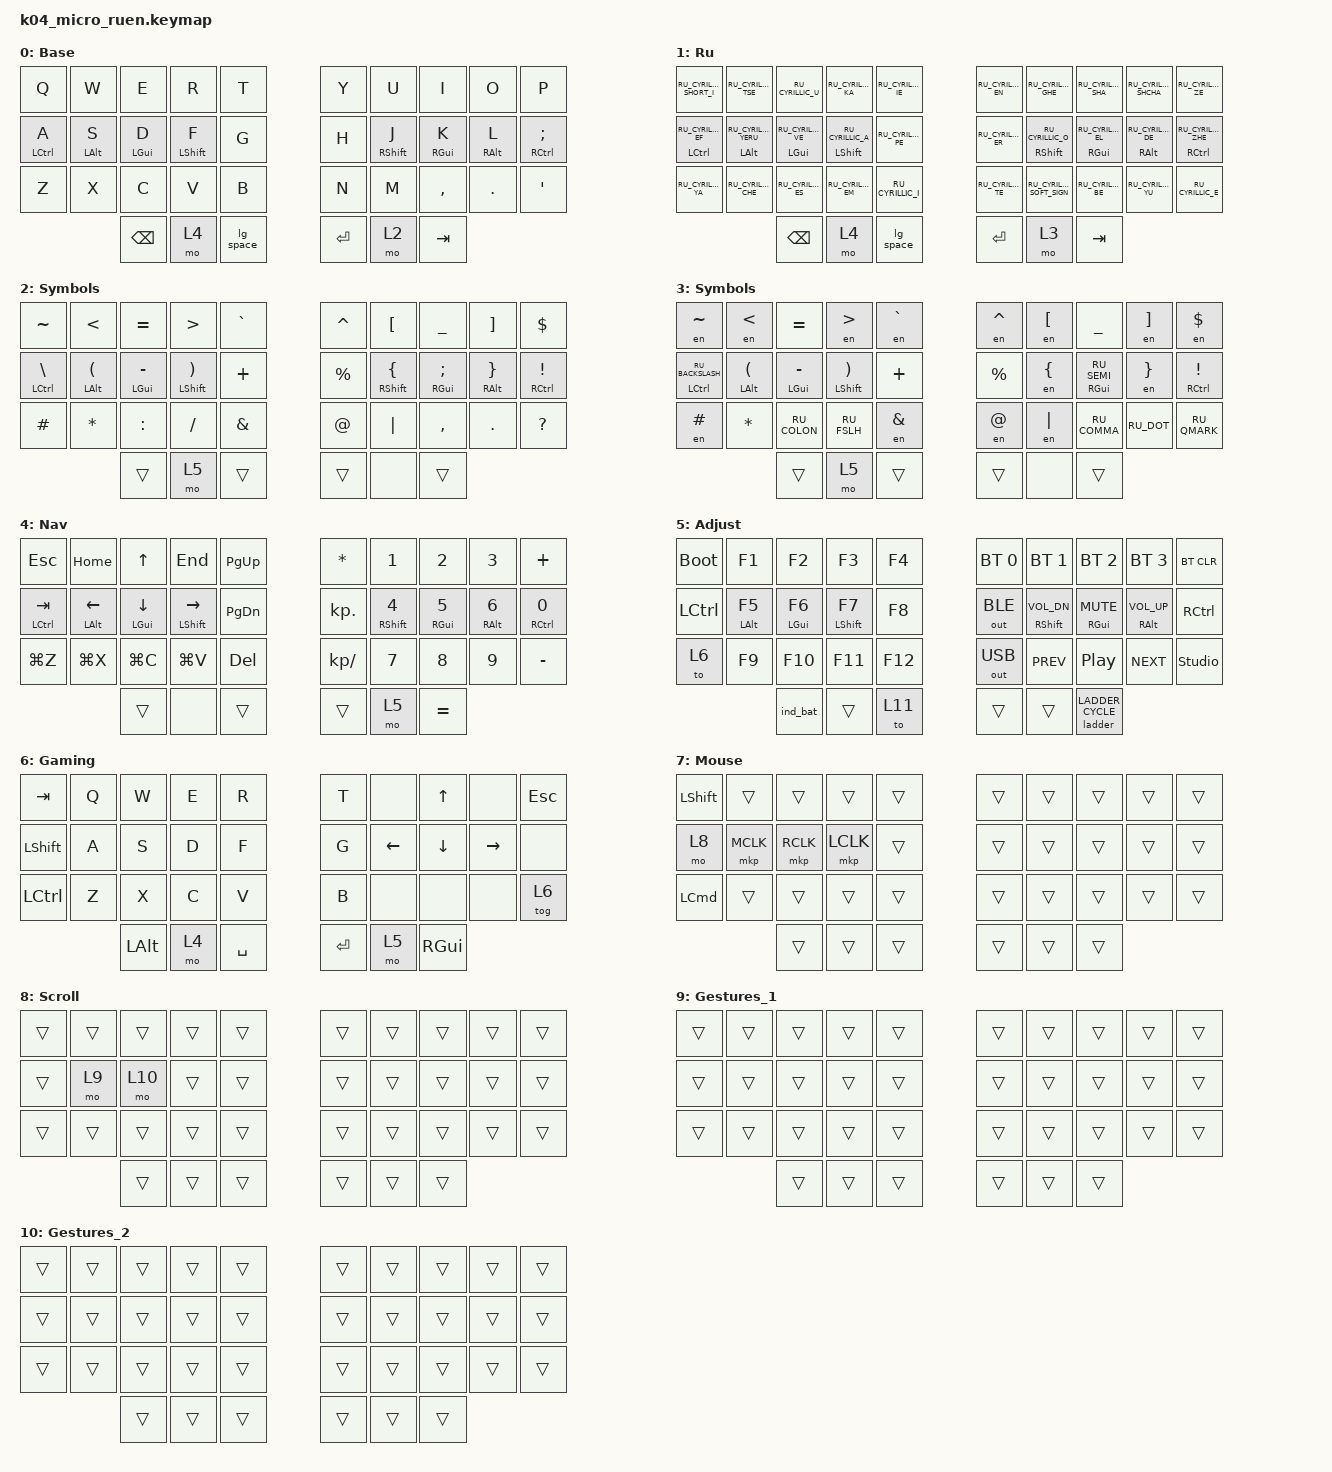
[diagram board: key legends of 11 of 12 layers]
/*
 * K:04 Micro — RU/EN вариант (аналог op36_ruen.keymap)
 * Слой Mouse включается сам при движении трекбола (zip_auto_mouse).
 */

#include "keys_ru.h"
#include <dt-bindings/zmk/input_transform.h>
#include <input/processors.dtsi>
#include <zephyr/dt-bindings/input/input-event-codes.h>
#include <behaviors/input_gestures_accel.dtsi>
#include <dt-bindings/zmk/mouse-gesture.h>
#include <behaviors.dtsi>
#include <behaviors/split_conn_ladder.dtsi>
#include <dt-bindings/zmk/split_conn_ladder.h>
#include <behaviors/ble_host_link.dtsi>
#include <dt-bindings/zmk/ble_host_link.h>
#include <dt-bindings/zmk/bt.h>
#include <dt-bindings/zmk/keys.h>
#include <dt-bindings/zmk/outputs.h>
#include <dt-bindings/zmk/pointing.h>

/ {
    input_processors {
        xy_fine: xy_fine {
            compatible = "zmk,input-processor-scaler";
            #input-processor-cells = <2>;
            type = <INPUT_EV_REL>;
            codes = <INPUT_REL_X INPUT_REL_Y>;
            track-remainders;
        };
    };

    accel_scroll: accel_scroll {
        compatible = "zmk,input-processor-acceleration";
        status = "okay";
        #input-processor-cells = <0>;
        input-type = <INPUT_EV_REL>;
        track-remainders;
        min-factor = <1000>;
        max-factor = <8000>;
        speed-threshold = <1000>;
        speed-max = <12000>;
        acceleration-exponent = <3>;
    };

    gest_layer_1: gest_layer_1 {
        compatible = "zmk,input-processor-mouse-gesture";
        #input-processor-cells = <0>;
        always-active;
        enable-eager-mode;
        suppress-movement;
        stroke-size = <120>;
        movement-threshold = <2>;
        gesture-cooldown-ms = <250>;

        gu {
            pattern = <GESTURE_UP>;
            bindings = <&gl_1_u>;
        };

        gd {
            pattern = <GESTURE_DOWN>;
            bindings = <&gl_1_d>;
        };

        gl {
            pattern = <GESTURE_LEFT>;
            bindings = <&gl_1_l>;
        };

        gr {
            pattern = <GESTURE_RIGHT>;
            bindings = <&gl_1_r>;
        };
    };

    gest_layer_2: gest_layer_2 {
        compatible = "zmk,input-processor-mouse-gesture";
        #input-processor-cells = <0>;
        always-active;
        enable-eager-mode;
        suppress-movement;
        stroke-size = <120>;
        movement-threshold = <2>;
        gesture-cooldown-ms = <250>;

        gu {
            pattern = <GESTURE_UP>;
            bindings = <&gl_2_u>;
        };

        gd {
            pattern = <GESTURE_DOWN>;
            bindings = <&gl_2_d>;
        };

        gl {
            pattern = <GESTURE_LEFT>;
            bindings = <&gl_2_l>;
        };

        gr {
            pattern = <GESTURE_RIGHT>;
            bindings = <&gl_2_r>;
        };
    };
};

&pointer_accel {
    input-type = <INPUT_EV_REL>;
    track-remainders;
    min-factor = <1000>;
    max-factor = <6000>;
    speed-threshold = <100>;
    speed-max = <16000>;
    acceleration-exponent = <2>;
};

&mt {
    quick-tap-ms = <200>;
    flavor = "tap-preferred";
    require-prior-idle-ms = <125>;
};

/ {
    behaviors {
        zip_auto_mouse: zip_auto_mouse {
            compatible = "zmk,input-processor-temp-layer-keep";
            #input-processor-cells = <2>;
            require-prior-idle-ms = <300>;
            excluded-positions = <0 10 11 12 13 20>;
            keep-active-while-layers = <8 9 10>;
        };

        hml: home_row_mod_left {
            compatible = "zmk,behavior-hold-tap";
            #binding-cells = <2>;
            flavor = "balanced";
            require-prior-idle-ms = <150>;
            tapping-term-ms = <280>;
            quick-tap-ms = <175>;
            bindings = <&kp>, <&kp>;

            hold-trigger-key-positions = <5 6 7 8 9 15 16 17 18 19 25 26 27 28 29 33 34 35 32>;
            hold-trigger-on-release;
        };

        hmr: home_row_mod_right {
            compatible = "zmk,behavior-hold-tap";
            #binding-cells = <2>;
            flavor = "balanced";
            require-prior-idle-ms = <150>;
            tapping-term-ms = <280>;
            quick-tap-ms = <175>;
            bindings = <&kp>, <&kp>;

            hold-trigger-key-positions = <0 1 2 3 4 10 11 12 13 14 20 21 22 23 24 30 31 32>;
            hold-trigger-on-release;
        };

        lg_space: lg_space {
            compatible = "zmk,behavior-mod-morph";
            label = "toggle 'ru' layer with LGUI";
            bindings = <&kp SPACE>, <&lg_tog>;

            #binding-cells = <0>;
            mods = <(MOD_LGUI|MOD_RGUI)>;
        };
    };

    combos {
        compatible = "zmk,combos";

        kha {
            bindings = <&kp RU_CYRILLIC_HA>;
            key-positions = <6 7>;
            layers = <1>;
        };

        hrdsgn {
            bindings = <&kp RU_CYRILLIC_HARD_SIGN>;
            key-positions = <7 8>;
            layers = <1>;
        };

        ru_io {
            bindings = <&kp RU_CYRILLIC_IO>;
            key-positions = <3 4>;
            layers = <1>;
        };

        cmbenru {
            bindings = <&tog 1>;
            key-positions = <2 3>;
            layers = <0 1>;
        };
    };

    macros {
        gl_1_u: gl_1_u {
            compatible = "zmk,behavior-macro";
            #binding-cells = <0>;
            display-name = "Gesture Up (1)";
            bindings = <&kp LC(UP)>;
            wait-ms = <0>;
            tap-ms = <30>;
        };

        gl_1_d: gl_1_d {
            compatible = "zmk,behavior-macro";
            #binding-cells = <0>;
            display-name = "Gesture Down (1)";
            bindings = <&none>;
            wait-ms = <0>;
            tap-ms = <30>;
        };

        gl_1_l: gl_1_l {
            compatible = "zmk,behavior-macro";
            #binding-cells = <0>;
            display-name = "Gesture Left (1)";
            bindings = <&kp LG(C)>;
            wait-ms = <0>;
            tap-ms = <30>;
        };

        gl_1_r: gl_1_r {
            compatible = "zmk,behavior-macro";
            #binding-cells = <0>;
            display-name = "Gesture Right (1)";
            bindings = <&kp LG(V)>;
            wait-ms = <0>;
            tap-ms = <30>;
        };

        gl_2_u: gl_2_u {
            compatible = "zmk,behavior-macro";
            #binding-cells = <0>;
            display-name = "Gesture Up (2)";
            bindings = <&kp LS(LC(TAB))>;
            wait-ms = <0>;
            tap-ms = <30>;
        };

        gl_2_d: gl_2_d {
            compatible = "zmk,behavior-macro";
            #binding-cells = <0>;
            display-name = "Gesture Down (2)";
            bindings = <&kp LC(TAB)>;
            wait-ms = <0>;
            tap-ms = <30>;
        };

        gl_2_l: gl_2_l {
            compatible = "zmk,behavior-macro";
            #binding-cells = <0>;
            display-name = "Gesture Left (2)";
            bindings = <&kp LG(W)>;
            wait-ms = <0>;
            tap-ms = <30>;
        };

        gl_2_r: gl_2_r {
            compatible = "zmk,behavior-macro";
            #binding-cells = <0>;
            display-name = "Gesture Right (2)";
            bindings = <&kp LG(T)>;
            wait-ms = <0>;
            tap-ms = <30>;
        };

        to_ru: to_ru {
            compatible = "zmk,behavior-macro";
            #binding-cells = <0>;
            bindings = <&kp LG(SPACE)>;
            label = "TO_RU";
            wait-ms = <0>;
            tap-ms = <30>;
        };

        to_en: to_en {
            compatible = "zmk,behavior-macro";
            #binding-cells = <0>;
            bindings = <&kp LG(SPACE)>;
            label = "TO_EN";
            wait-ms = <0>;
            tap-ms = <30>;
        };

        layer_en: layer_en {
            compatible = "zmk,behavior-macro";
            #binding-cells = <0>;
            bindings = <&to 0 &to_en>;
            label = "LAYER_EN";
            wait-ms = <0>;
            tap-ms = <30>;
        };

        layer_ru: layer_ru {
            compatible = "zmk,behavior-macro";
            #binding-cells = <0>;
            bindings = <&to 1 &to_ru>;
            label = "LAYER_RU";
            tap-ms = <30>;
            wait-ms = <0>;
        };

        en: en {
            compatible = "zmk,behavior-macro-one-param";
            #binding-cells = <1>;
            bindings =
                <&to_en>,
                <&macro_press>,
                <&macro_param_1to1 &kp MACRO_PLACEHOLDER>,
                <&macro_pause_for_release>,
                <&macro_release>,
                <&macro_param_1to1 &kp MACRO_PLACEHOLDER>,
                <&macro_tap>,
                <&to_ru>;

            label = "EN";
            wait-ms = <0>;
            tap-ms = <30>;
        };

        lg_tog: lg_tog {
            compatible = "zmk,behavior-macro";
            #binding-cells = <0>;
            bindings = <&kp LG(SPACE) &tog 1>;
            label = "LG_TOG";
        };
    };

    keymap {
        compatible = "zmk,keymap";

        en {
            bindings = <
&kp Q         &kp W        &kp E        &kp R          &kp T                          &kp Y  &kp U         &kp I        &kp O        &kp P
&hml LCTRL A  &hml LALT S  &hml LGUI D  &hml LSHFT F   &kp G                          &kp H  &hmr RSHFT J  &hmr RGUI K  &hmr RALT L  &hmr RCTRL SEMICOLON
&kp Z         &kp X        &kp C        &kp V          &kp B                          &kp N  &kp M         &kp COMMA    &kp DOT      &kp SQT
                                        &kp BACKSPACE  &mo 4  &lg_space    &kp ENTER  &mo 2  &kp TAB
            >;

            display-name = "Base";
        };

        ru {
            bindings = <
&kp RU_CYRILLIC_SHORT_I    &kp RU_CYRILLIC_TSE         &kp RU_CYRILLIC_U         &kp RU_CYRILLIC_KA        &kp RU_CYRILLIC_IE                          &kp RU_CYRILLIC_EN  &kp RU_CYRILLIC_GHE        &kp RU_CYRILLIC_SHA       &kp RU_CYRILLIC_SHCHA     &kp RU_CYRILLIC_ZE
&hml LCTRL RU_CYRILLIC_EF  &hml LALT RU_CYRILLIC_YERU  &hml LGUI RU_CYRILLIC_VE  &hml LSHFT RU_CYRILLIC_A  &kp RU_CYRILLIC_PE                          &kp RU_CYRILLIC_ER  &hmr RSHFT RU_CYRILLIC_O   &hmr RGUI RU_CYRILLIC_EL  &hmr RALT RU_CYRILLIC_DE  &hmr RCTRL RU_CYRILLIC_ZHE
&kp RU_CYRILLIC_YA         &kp RU_CYRILLIC_CHE         &kp RU_CYRILLIC_ES        &kp RU_CYRILLIC_EM        &kp RU_CYRILLIC_I                           &kp RU_CYRILLIC_TE  &kp RU_CYRILLIC_SOFT_SIGN  &kp RU_CYRILLIC_BE        &kp RU_CYRILLIC_YU        &kp RU_CYRILLIC_E
                                                                                 &kp BACKSPACE             &mo 4               &lg_space    &kp ENTER  &mo 3               &kp TAB
            >;

            display-name = "Ru";
        };

        sym_en {
            bindings = <
&kp TILDE        &kp LT          &kp EQUAL        &kp GT           &kp GRAVE                    &kp CARET  &kp LBKT         &kp UNDER       &kp RBKT        &kp DLLR
&hml LCTRL BSLH  &hml LALT LPAR  &hml LGUI MINUS  &hml LSHFT RPAR  &kp PLUS                     &kp PRCNT  &hmr RSHFT LBRC  &hmr RGUI SEMI  &hmr RALT RBRC  &hmr RCTRL EXCL
&kp HASH         &kp STAR        &kp COLON        &kp FSLH         &kp AMPS                     &kp AT     &kp PIPE         &kp COMMA       &kp DOT         &kp QMARK
                                                  &trans           &mo 5      &trans    &trans  &none      &trans
            >;

            display-name = "Symbols";
        };

        sym_ru {
            bindings = <
&en TILDE                &en LT          &kp EQUAL        &en GT           &en GRAVE                    &en CARET  &en LBKT  &kp UNDER          &en RBKT    &en DLLR
&hml LCTRL RU_BACKSLASH  &hml LALT LPAR  &hml LGUI MINUS  &hml LSHFT RPAR  &kp PLUS                     &kp PRCNT  &en LBRC  &hmr RGUI RU_SEMI  &en RBRC    &hmr RCTRL EXCL
&en HASH                 &kp STAR        &kp RU_COLON     &kp RU_FSLH      &en AMPS                     &en AT     &en PIPE  &kp RU_COMMA       &kp RU_DOT  &kp RU_QMARK
                                                          &trans           &mo 5      &trans    &trans  &none      &trans
            >;

            display-name = "Symbols";
        };

        nav {
            bindings = <
&kp ESC         &kp HOME            &kp UP          &kp END           &kp PAGE_UP                      &kp STAR       &kp N1         &kp N2        &kp N3        &kp PLUS
&hml LCTRL TAB  &hml LEFT_ALT LEFT  &hml LGUI DOWN  &hml LSHFT RIGHT  &kp PAGE_DOWN                    &kp KP_DOT     &hmr RSHFT N4  &hmr RGUI N5  &hmr RALT N6  &hmr RCTRL N0
&kp LG(Z)       &kp LG(X)           &kp LG(C)       &kp LG(V)         &kp DELETE                       &kp KP_DIVIDE  &kp N7         &kp N8        &kp N9        &kp MINUS
                                                    &trans            &none          &trans    &trans  &mo 5          &kp EQUAL
            >;

            display-name = "Nav";
        };

        adj {
            bindings = <
&bootloader  &kp F1        &kp F2        &kp F3         &kp F4                     &bt BT_SEL 0  &bt BT_SEL 1         &bt BT_SEL 2      &bt BT_SEL 3        &bt BT_CLR
&kp LCTRL    &hml LALT F5  &hml LGUI F6  &hml LSHFT F7  &kp F8                     &out OUT_BLE  &hmr RSHFT C_VOL_DN  &hmr RGUI C_MUTE  &hmr RALT C_VOL_UP  &kp RCTRL
&to 6        &kp F9        &kp F10       &kp F11        &kp F12                    &out OUT_USB  &kp C_PREV           &kp C_PP          &kp C_NEXT          &studio_unlock
                                         &ind_bat       &trans   &to 11    &trans  &trans        &ladder LADDER_CYCLE
            >;

            display-name = "Adjust";
        };

        game {
            bindings = <
&kp TAB    &kp Q  &kp W  &kp E         &kp R                          &kp T  &none     &kp UP    &none            &kp ESC
&kp LSHFT  &kp A  &kp S  &kp D         &kp F                          &kp G  &kp LEFT  &kp DOWN  &kp RIGHT_ARROW  &none
&kp LCTRL  &kp Z  &kp X  &kp C         &kp V                          &kp B  &none     &none     &none            &tog 6
                         &kp LEFT_ALT  &mo 4  &kp SPACE    &kp ENTER  &mo 5  &kp RGUI
            >;

            label = "Gaming";
        };

        mouse {
            bindings = <
&kp LEFT_SHIFT    &trans     &trans     &trans     &trans                    &trans  &trans  &trans  &trans  &trans
&mo 8             &mkp MCLK  &mkp RCLK  &mkp LCLK  &trans                    &trans  &trans  &trans  &trans  &trans
&kp LEFT_COMMAND  &trans     &trans     &trans     &trans                    &trans  &trans  &trans  &trans  &trans
                                        &trans     &trans  &trans    &trans  &trans  &trans
            >;

            display-name = "Mouse";
        };

        scroll {
            bindings = <
&trans  &trans  &trans  &trans  &trans                    &trans  &trans  &trans  &trans  &trans
&trans  &mo 9   &mo 10  &trans  &trans                    &trans  &trans  &trans  &trans  &trans
&trans  &trans  &trans  &trans  &trans                    &trans  &trans  &trans  &trans  &trans
                        &trans  &trans  &trans    &trans  &trans  &trans
            >;

            display-name = "Scroll";
        };

        gest_1 {
            bindings = <
&trans  &trans  &trans  &trans  &trans                    &trans  &trans  &trans  &trans  &trans
&trans  &trans  &trans  &trans  &trans                    &trans  &trans  &trans  &trans  &trans
&trans  &trans  &trans  &trans  &trans                    &trans  &trans  &trans  &trans  &trans
                        &trans  &trans  &trans    &trans  &trans  &trans
            >;

            display-name = "Gestures_1";
        };

        gest_2 {
            bindings = <
&trans  &trans  &trans  &trans  &trans                    &trans  &trans  &trans  &trans  &trans
&trans  &trans  &trans  &trans  &trans                    &trans  &trans  &trans  &trans  &trans
&trans  &trans  &trans  &trans  &trans                    &trans  &trans  &trans  &trans  &trans
                        &trans  &trans  &trans    &trans  &trans  &trans
            >;

            display-name = "Gestures_2";
        };

        /* Layer 11. Host link tests: intervals in 1.25 ms units, latency in
           connection events, ball reports in ms. Reach it with &to 11 (bind it
           where you like, or through ZMK Studio); &to 0 on both outer thumbs
           leaves it. */
        ble_host_link_tests {
            bindings = <
&ble_host_link BLE_HOST_INTERVAL_PREV  &ble_host_link BLE_HOST_INTERVAL_NEXT  &ble_host_link BLE_HOST_INTERVAL_SET 6   &ble_host_link BLE_HOST_INTERVAL_SET 9   &ble_host_link BLE_HOST_INTERVAL_SET 12                                              &bt BT_SEL 0                                                         &bt BT_SEL 1                                                         &bt BT_SEL 2                                                         &bt BT_SEL 3                                                 &out OUT_BLE
&ble_host_link BLE_HOST_LATENCY_PREV   &ble_host_link BLE_HOST_LATENCY_NEXT   &ble_host_link BLE_HOST_LATENCY_SET 0    &ble_host_link BLE_HOST_LATENCY_SET 30   &ble_host_link BLE_HOST_LATENCY_SET BLE_HOST_LATENCY_AUTO                            &ble_host_link BLE_HOST_INTERVAL_SET BLE_HOST_INTERVAL_RANGE(9, 21)  &ble_host_link BLE_HOST_INTERVAL_SET BLE_HOST_INTERVAL_RANGE(10, 22)  &ble_host_link BLE_HOST_INTERVAL_SET BLE_HOST_INTERVAL_RANGE(11, 23)  &ble_host_link BLE_HOST_INTERVAL_SET BLE_HOST_INTERVAL_AUTO  &out OUT_USB
&ble_host_link BALL_BLE_REPORT_PREV    &ble_host_link BALL_BLE_REPORT_NEXT    &ble_host_link BALL_BLE_REPORT_SET 4     &ble_host_link BALL_BLE_REPORT_SET 8     &ble_host_link BALL_BLE_REPORT_SET BALL_BLE_REPORT_AUTO                              &ble_host_link BLE_HOST_LINK_AUTO                                    &ble_host_link BLE_HOST_LINK_REQUEST_AGAIN                           &ble_host_link BLE_HOST_LINK_SHOW                                    &ble_host_link BLE_HOST_LINK_TYPE_REPORT                     &trans
                                                                                                                  &to 0                                    &trans                                                               &trans                                                               &trans                                                               &trans                                                       &to 0
            >;

            display-name = "BLE host tests";
        };
    };
};

&trackball_listener {
    input-processors =
        <&zip_auto_mouse 7 500>,
        <&pointer_accel>,
        <&xy_fine 2 5>;

    gestures_layer_1 {
        layers = <9>;
        input-processors = <&gest_layer_1>;
    };

    gestures_layer_2 {
        layers = <10>;
        input-processors = <&gest_layer_2>;
    };

    scroller {
        layers = <8>;
        input-processors =
            <&zip_xy_transform INPUT_TRANSFORM_Y_INVERT>,
            <&accel_scroll>,
            <&xy_fine 1 100>,
            <&zip_xy_to_scroll_mapper>;
    };
};

&mkp_input_listener { input-processors = <&zip_auto_mouse 7 500>; };
